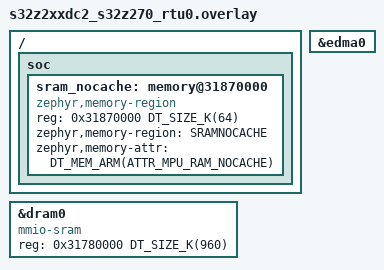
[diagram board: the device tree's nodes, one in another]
/*
 * Copyright 2024 NXP
 *
 * SPDX-License-Identifier: Apache-2.0
 */

#include <zephyr/dt-bindings/memory-attr/memory-attr-arm.h>

/ {
	soc {
		sram_nocache: memory@31870000 {
			compatible = "zephyr,memory-region", "mmio-sram";
			reg = <0x31870000 DT_SIZE_K(64)>;
			zephyr,memory-region = "SRAMNOCACHE";
			zephyr,memory-attr = <DT_MEM_ARM(ATTR_MPU_RAM_NOCACHE)>;
		};
	};
};

&dram0 {
	compatible = "mmio-sram";
	reg = <0x31780000 DT_SIZE_K(960)>;
};

&edma0 {
	status = "okay";
};

tst_dma0: &edma0 {};
